# H3 register map
Vendor: Allwinner; Series: H3; File version: 0.1
CPU: 0, little endian, MPU, no FPU, 0 interrupt priority bits
Registers are 32-bit, read-write, reset 0x0 unless marked. A register's access mark holds for its fields unless they carry their own. Offsets are from the block's base; [hi:lo] are bit positions; {n}, {i} and the like mark numbered series.

## SMTA
Base 0x01C23400
{0x4+0xC*i} SMTA_DECPORT{i}_STA_REG (i=0..2) — SMTA Decode Port{i} Status Register
  [7:0] STA_DEC_PROT{i}_OUT ro — Show the status of the decode protection output: 0: = Decode region corresponding to the bit is secure 1: = Decode region corresponding to the bit is non-secure. There is one bit of the register for each protection output (See the SMTA Configuration Table4-6 in detail).
{0x8+0xC*i} SMTA_DECPORT{i}_SET_REG (i=0..2) — SMTA Decode Port{i} Set Register
  [7:0] SET_DEC_PORT{i}_OUT wo — Sets the corresponding decode protection output: 0: = No effect 1: = Set decode region to non-secure. There is one bit of the register for each protection output (See the SMTA Configuration Table4-6 in detail).
{0xC+0xC*i} SMTA_DECPORT{i}_CLR_REG (i=0..2) — SMTA Decode Port{i} Clear Register
  [7:0] CLR_DEC_PROT{i}_OUT wo — Clears the corresponding decode protection output: 0: = No effect 1: = Set decode region to secure. There is one bit of the register for each protection output (See the SMTA Configuration Table4-6 in detail).

## SPINLOCK
Base 0x01C18000
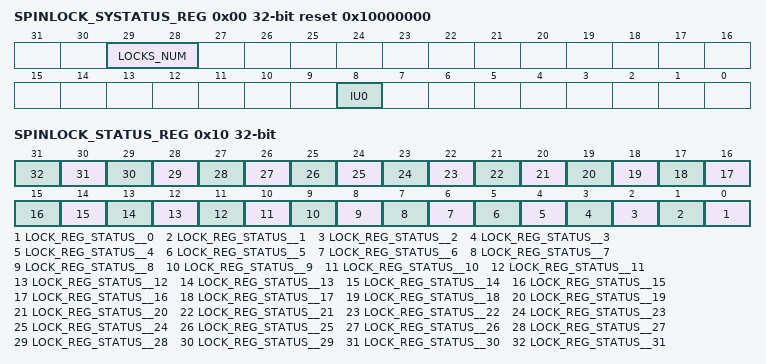
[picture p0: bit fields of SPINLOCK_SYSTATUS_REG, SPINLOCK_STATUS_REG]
0x00 SPINLOCK_SYSTATUS_REG reset 0x10000000 — Spinlock System Status Register
  [29:28] LOCKS_NUM ro — Number of lock registers implemented. 0x1: This instance has 32 lock registers. 0x2: This instance has 64 lock registers. 0x3: This instance has 128 lock registers. 0x4: This instance has 256 lock registers.
    1=This instance has 32 lock registers; 2=This instance has 64 lock registers; 3=This instance has 128 lock registers; 4=This instance has 256 lock registers
  [8] IU0 ro — In-Use flag0, covering lock register0-31. 0: All lock register 0-31 are in the Not Taken state. 1: At least one of the lock register 0-31 is in the Taken state.
    0=All (All lock register 0-31 are in the Not Taken state.); 1=At (At least one of the lock register 0-31 is in the Taken state.)
0x10 SPINLOCK_STATUS_REG — Spinlock Status Register
  [n] LOCK_REG_STATUS__{n} ro (n=0..31) — SpinLock[i] status (i=0~31) 0: The Spinlock is free, 1: The Spinlock is taken.
{0x100+4i} SPINLOCKN_LOCK_REG[{i}] (i=0..31) — SPINLOCKN_LOCK_REG[{i}]
  [0] TAKEN — Lock State. Read 0x0: The lock was previously Not Taken (free).The requester is granted the lock. Write 0x0: Set the lock to Not Taken (free). Read 0x1: The lock was previously Taken. The requester is not granted the lock and must retry. Write 0x1: No update to the lock value.

## TWD
Base 0x01F01800
0x00 TWD_STATUS_REG — TWD Status Register
  [0] TWD_PEND_FLAG — Interrupt pending. Set 1 to the bit will clear it. 0: No effect. 1: Pending.
    0=No_effect; 1=Pending
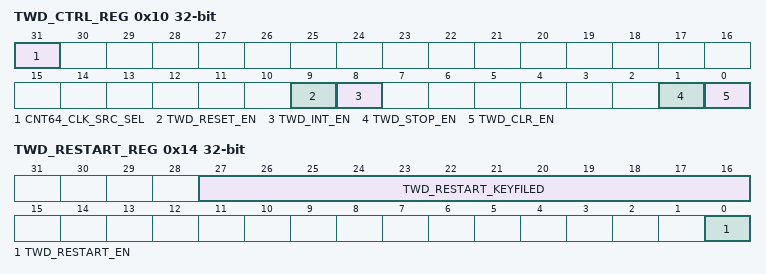
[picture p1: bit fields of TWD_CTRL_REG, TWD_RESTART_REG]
0x10 TWD_CTRL_REG — TWD Control Register
  [31] CNT64_CLK_SRC_SEL — 64-bit counter clock source select. 0: LOSC. 1: OSC24M.
    0=LOSC; 1=OSC24M
  [9] TWD_RESET_EN — TWD reset enable. 0: Reset disable. 1: Reset enable.
    0=Reset_disable; 1=Reset_enable
  [8] TWD_INT_EN — TWD Interrupt Enable. 0: Interrupt disable. 1: Interrupt enable.
    0=Interrupt_disable; 1=Interrupt_enable
  [1] TWD_STOP_EN — TWD stop enable. 0: Resume rolling-over. 1: Stop rolling-over.
    0=Resume rolling-over; 1=Stop rolling-over
  [0] TWD_CLR_EN — TWD clear enable. 0: No effect. 1: To clear relevant registers and it will change to zero after the registers are cleared.
    0=No_effect; 1=To clear relevant registers and it will change to zero after the registers are cleared
0x14 TWD_RESTART_REG — TWD Restart Register
  [27:16] TWD_RESTART_KEYFILED wo — Should be written at value 0xD14. Writing any other value in this field aborts the write operation.
  [0] TWD_RESTART_EN wo — If writing `1` in this bit, the value of would change. 0: No effect. 1: Restart enable.
    0=No_effect; 1=Restart enable
0x20 TWD_LOW_CNT_REG — TWD Low Counter Register
  [31:0] TWD_LOW_CNT ro — The TWD low 32-bit counter.
0x24 TWD_HIGH_CNT_REG — TWD High Counter Register
  [31:0] TWD_HIGH_CNT ro — The TWD high 32-bit counter.
0x30 TWD_INTV_VAL_REG — TWD Interval Value Register
  [31:0] TWD_INTV_VAL — The TWD interval value.
0x40 TWD_LOW_CNT_CMP_REG — TWD Low Counter Compare Register
  [31:0] TWD_LOW_CMP ro — The TWD low 32-bit compare counter.
0x44 TWD_HIGH_CNT_CMP_REG — TWD High Counter Compare Register
  [31:0] TWD_HIGH_CMP ro — The TWD high 32-bit compare counter.
0x100 SST_NV_CNT_REG — Secure Storage NV-Counter Register
  [31:0] SST_NV_CNT — This counter protects the trusted world Secure Storage file from replay attacks.
{0x110+4i} SYN_DATA_CNT_REG{i} (i=0..3) — Synchronize Data Counter Register {i}
  [31:0] SYN_DATA_CNT{i} — This counter is used for synchronizing data stores against replay attacks.
